AUTOSAR XML (schema 00051)
package /Components
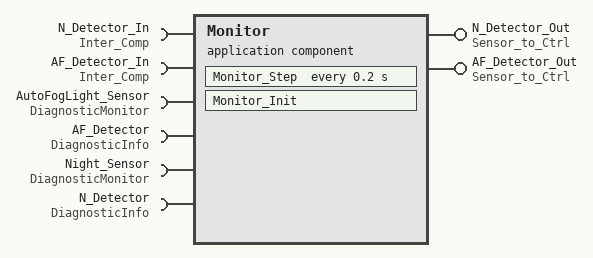
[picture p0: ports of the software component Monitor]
  application sw component type Monitor
    require port N_Detector_In: nonqueued-receiver-com-spec{data-element=Value, init-value=0}, required-interface=Inter_Comp
    require port AF_Detector_In: nonqueued-receiver-com-spec{data-element=Value, init-value=0}, required-interface=Inter_Comp
    provide port N_Detector_Out: nonqueued-sender-com-spec{data-element=Value, init-value=0}, provided-interface=Sensor_to_Ctrl
    provide port AF_Detector_Out: nonqueued-sender-com-spec{data-element=Value, init-value=0}, provided-interface=Sensor_to_Ctrl
    4 x require port:
      AutoFogLight_Sensor: required-interface=DiagnosticMonitor
      AF_Detector: required-interface=DiagnosticInfo
      Night_Sensor: required-interface=DiagnosticMonitor
      N_Detector: required-interface=DiagnosticInfo
    behavior Monitor_IB: handle-termination-and-restart=NO-SUPPORT
      timing event Event_Monitor_Step: start-on-event=Monitor_Step, period=0.2
      runnable Monitor_Init
      runnable Monitor_Step
        data-read-access:
          access IN_N_Detector_In_Value: accessed-variable=N_Detector_In.Value
          access IN_AF_Detector_In_Value: accessed-variable=AF_Detector_In.Value
        data-write-access:
          access OUT_N_Detector_Out_Value: accessed-variable=N_Detector_Out.Value
          access OUT_AF_Detector_Out_Value: accessed-variable=AF_Detector_Out.Value
        4 x sync call, all with timeout=1.0E-06:
          SC_AF_Detector_GetEventUdsStatus: operation=AF_Detector.GetEventUdsStatus
          SC_AutoFogLight_Sensor_SetEventStatus: operation=AutoFogLight_Sensor.SetEventStatus
          SC_N_Detector_GetEventUdsStatus: operation=N_Detector.GetEventUdsStatus
          SC_Night_Sensor_SetEventStatus: operation=Night_Sensor.SetEventStatus
